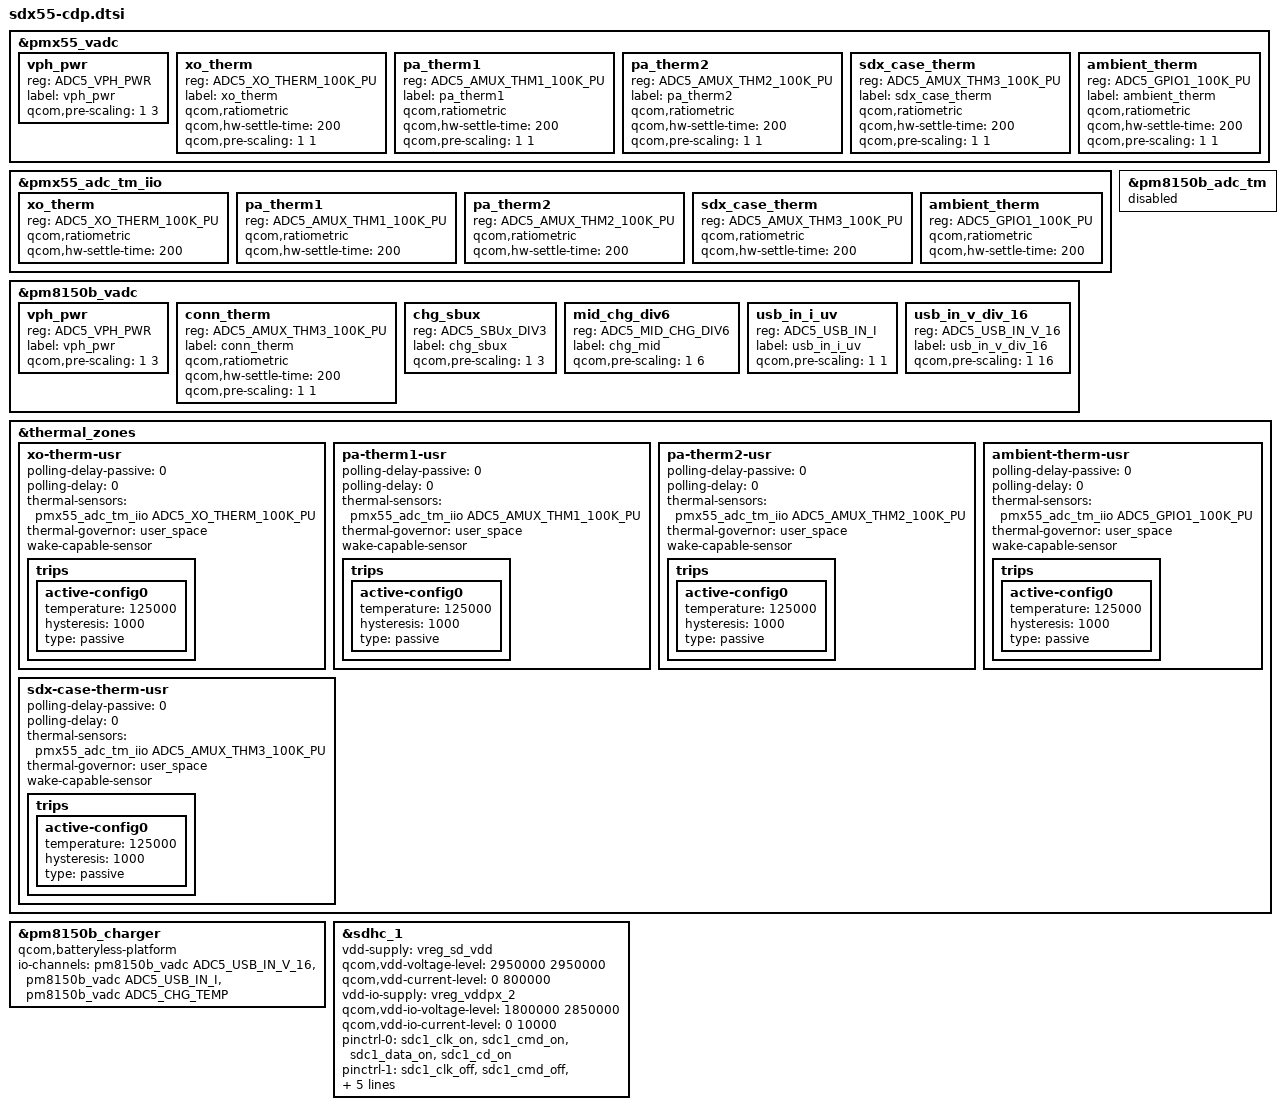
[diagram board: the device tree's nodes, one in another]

#include "sdx55-pmic-overlay.dtsi"
#include "sa515m-cdp-audio-overlay.dtsi"
#include "pm8150b.dtsi"

&pmx55_vadc {
	vph_pwr {
		reg = <ADC5_VPH_PWR>;
		label = "vph_pwr";
		qcom,pre-scaling = <1 3>;
	};

	xo_therm {
		reg = <ADC5_XO_THERM_100K_PU>;
		label = "xo_therm";
		qcom,ratiometric;
		qcom,hw-settle-time = <200>;
		qcom,pre-scaling = <1 1>;
	};

	pa_therm1 {
		reg = <ADC5_AMUX_THM1_100K_PU>;
		label = "pa_therm1";
		qcom,ratiometric;
		qcom,hw-settle-time = <200>;
		qcom,pre-scaling = <1 1>;
	};

	pa_therm2 {
		reg = <ADC5_AMUX_THM2_100K_PU>;
		label = "pa_therm2";
		qcom,ratiometric;
		qcom,hw-settle-time = <200>;
		qcom,pre-scaling = <1 1>;
	};

	sdx_case_therm {
		reg = <ADC5_AMUX_THM3_100K_PU>;
		label = "sdx_case_therm";
		qcom,ratiometric;
		qcom,hw-settle-time = <200>;
		qcom,pre-scaling = <1 1>;
	};

	ambient_therm {
		reg = <ADC5_GPIO1_100K_PU>;
		label = "ambient_therm";
		qcom,ratiometric;
		qcom,hw-settle-time = <200>;
		qcom,pre-scaling = <1 1>;
	};
};

&pmx55_adc_tm_iio {
	xo_therm {
		reg = <ADC5_XO_THERM_100K_PU>;
		qcom,ratiometric;
		qcom,hw-settle-time = <200>;
	};

	pa_therm1 {
		reg = <ADC5_AMUX_THM1_100K_PU>;
		qcom,ratiometric;
		qcom,hw-settle-time = <200>;
	};

	pa_therm2 {
		reg = <ADC5_AMUX_THM2_100K_PU>;
		qcom,ratiometric;
		qcom,hw-settle-time = <200>;
	};

	sdx_case_therm {
		reg = <ADC5_AMUX_THM3_100K_PU>;
		qcom,ratiometric;
		qcom,hw-settle-time = <200>;
	};

	ambient_therm {
		reg = <ADC5_GPIO1_100K_PU>;
		qcom,ratiometric;
		qcom,hw-settle-time = <200>;
	};
};

&pm8150b_vadc {
	vph_pwr {
		reg = <ADC5_VPH_PWR>;
		label = "vph_pwr";
		qcom,pre-scaling = <1 3>;
	};

	conn_therm {
		reg = <ADC5_AMUX_THM3_100K_PU>;
		label = "conn_therm";
		qcom,ratiometric;
		qcom,hw-settle-time = <200>;
		qcom,pre-scaling = <1 1>;
	};

	chg_sbux {
		reg = <ADC5_SBUx_DIV3>;
		label = "chg_sbux";
		qcom,pre-scaling = <1 3>;
	};

	mid_chg_div6 {
		reg = <ADC5_MID_CHG_DIV6>;
		label = "chg_mid";
		qcom,pre-scaling = <1 6>;
	};

	usb_in_i_uv {
		reg = <ADC5_USB_IN_I>;
		label = "usb_in_i_uv";
		qcom,pre-scaling = <1 1>;
	};

	usb_in_v_div_16 {
		reg = <ADC5_USB_IN_V_16>;
		label = "usb_in_v_div_16";
		qcom,pre-scaling = <1 16>;
	};
};

&pm8150b_adc_tm {
	status = "disabled";
};

&thermal_zones {
	xo-therm-usr {
		polling-delay-passive = <0>;
		polling-delay = <0>;
		thermal-sensors = <&pmx55_adc_tm_iio ADC5_XO_THERM_100K_PU>;
		thermal-governor = "user_space";
		wake-capable-sensor;

		trips {
			active-config0 {
				temperature = <125000>;
				hysteresis = <1000>;
				type = "passive";
			};
		};
	};

	pa-therm1-usr {
		polling-delay-passive = <0>;
		polling-delay = <0>;
		thermal-sensors = <&pmx55_adc_tm_iio ADC5_AMUX_THM1_100K_PU>;
		thermal-governor = "user_space";
		wake-capable-sensor;

		trips {
			active-config0 {
				temperature = <125000>;
				hysteresis = <1000>;
				type = "passive";
			};
		};
	};

	pa-therm2-usr {
		polling-delay-passive = <0>;
		polling-delay = <0>;
		thermal-sensors = <&pmx55_adc_tm_iio ADC5_AMUX_THM2_100K_PU>;
		thermal-governor = "user_space";
		wake-capable-sensor;

		trips {
			active-config0 {
				temperature = <125000>;
				hysteresis = <1000>;
				type = "passive";
			};
		};
	};

	sdx-case-therm-usr {
		polling-delay-passive = <0>;
		polling-delay = <0>;
		thermal-sensors = <&pmx55_adc_tm_iio ADC5_AMUX_THM3_100K_PU>;
		thermal-governor = "user_space";
		wake-capable-sensor;

		trips {
			active-config0 {
				temperature = <125000>;
				hysteresis = <1000>;
				type = "passive";
			};
		};
	};

	ambient-therm-usr {
		polling-delay-passive = <0>;
		polling-delay = <0>;
		thermal-sensors = <&pmx55_adc_tm_iio ADC5_GPIO1_100K_PU>;
		thermal-governor = "user_space";
		wake-capable-sensor;

		trips {
			active-config0 {
				temperature = <125000>;
				hysteresis = <1000>;
				type = "passive";
			};
		};
	};
};

&pm8150b_charger {
	qcom,batteryless-platform;
	io-channels = <&pm8150b_vadc ADC5_USB_IN_V_16>,
		      <&pm8150b_vadc ADC5_USB_IN_I>,
		      <&pm8150b_vadc ADC5_CHG_TEMP>;
	io-channel-names = "usb_in_voltage",
			   "usb_in_current",
			   "chg_temp";
};

&sdhc_1 {
	vdd-supply = <&vreg_sd_vdd>;
	qcom,vdd-voltage-level = <2950000 2950000>;
	qcom,vdd-current-level = <0 800000>;

	vdd-io-supply = <&vreg_vddpx_2>;
	qcom,vdd-io-voltage-level = <1800000 2850000>;
	qcom,vdd-io-current-level = <0 10000>;

	pinctrl-names = "active", "sleep";
	pinctrl-0 = <&sdc1_clk_on &sdc1_cmd_on &sdc1_data_on &sdc1_cd_on>;
	pinctrl-1 = <&sdc1_clk_off &sdc1_cmd_off &sdc1_data_off &sdc1_cd_off>;

	qcom,clk-rates = <400000 20000000 25000000 50000000 100000000
								200000000>;
	qcom,devfreq,freq-table = <50000000 200000000>;

	cd-gpios = <&tlmm 99 GPIO_ACTIVE_LOW>;
	status = "ok";
};
